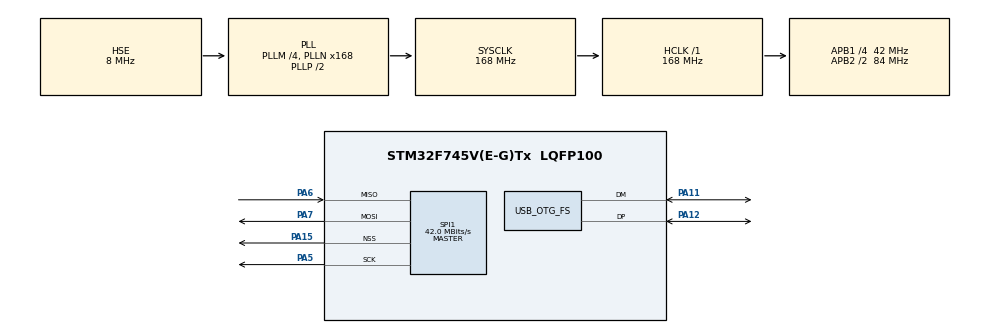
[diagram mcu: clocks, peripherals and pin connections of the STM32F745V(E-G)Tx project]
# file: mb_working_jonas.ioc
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FREERTOS.Mutexes01=sb_1_mutex,Static,myMutex01ControlBlock
FREERTOS.Tasks01=defaultTask,24,128,StartDefaultTask,Default,NULL,Dynamic,NULL,NULL;task_state_est,8,512,vTaskStateEst,Default,NULL,Static,task_sfBuffer,task_sfControlBlock;task_controller,8,512,vTaskController,Default,NULL,Static,task_controllerBuffer,task_controllerControlBlock;task_sens_read,8,512,vTaskSensRead,Default,NULL,Static,task_sensor_reaBuffer,task_sensor_reaControlBlock
Mcu.Family=STM32F7
Mcu.Name=STM32F745V(E-G)Tx
Mcu.Package=LQFP100
NVIC.OTG_FS_IRQn=true\:5\:0\:false\:false\:true\:true\:false\:true
NVIC.PriorityGroup=NVIC_PRIORITYGROUP_4
NVIC.TIM1_UP_TIM10_IRQn=true\:0\:0\:false\:false\:true\:false\:false\:true
NVIC.TimeBase=TIM1_UP_TIM10_IRQn
NVIC.TimeBaseIP=TIM1
PA11.Mode=Device_Only
PA11.Signal=USB_OTG_FS_DM
PA12.Mode=Device_Only
PA12.Signal=USB_OTG_FS_DP
PA15.Mode=NSS_Signal_Hard_Output
PA15.Signal=SPI1_NSS
PA5.Mode=Full_Duplex_Master
PA5.Signal=SPI1_SCK
PA6.Mode=Full_Duplex_Master
PA6.Signal=SPI1_MISO
PA7.Mode=Full_Duplex_Master
PA7.Signal=SPI1_MOSI
PH0/OSC_IN.Mode=HSE-External-Oscillator
PH0/OSC_IN.Signal=RCC_OSC_IN
PH1/OSC_OUT.Mode=HSE-External-Oscillator
PH1/OSC_OUT.Signal=RCC_OSC_OUT
ProjectManager.HeapSize=0x400
ProjectManager.StackSize=0x800
ProjectManager.TargetToolchain=STM32CubeIDE
RCC.AHBFreq_Value=168000000
RCC.APB1CLKDivider=RCC_HCLK_DIV4
RCC.APB1Freq_Value=42000000
RCC.APB1TimFreq_Value=84000000
RCC.APB2CLKDivider=RCC_HCLK_DIV2
RCC.APB2Freq_Value=84000000
RCC.APB2TimFreq_Value=168000000
RCC.CortexFreq_Value=168000000
RCC.HCLKFreq_Value=168000000
RCC.HSE_VALUE=8000000
RCC.HSI_VALUE=16000000
RCC.LSE_VALUE=32768
RCC.PLLM=4
RCC.PLLN=168
RCC.PLLQ=7
RCC.SYSCLKFreq_VALUE=168000000
RCC.SYSCLKSource=RCC_SYSCLKSOURCE_PLLCLK
RCC.USBFreq_Value=48000000
RCC.VCOOutputFreq_Value=336000000
SPI1.CalculateBaudRate=42.0 MBits/s
SPI1.DataSize=SPI_DATASIZE_8BIT
SPI1.Direction=SPI_DIRECTION_2LINES
SPI1.Mode=SPI_MODE_MASTER
SPI1.VirtualNSS=VM_NSSHARD
SPI1.VirtualType=VM_MASTER
USB_DEVICE.CLASS_NAME_FS=CDC
USB_DEVICE.VirtualMode-CDC_FS=Cdc
USB_DEVICE.VirtualModeFS=Cdc_FS
USB_OTG_FS.VirtualMode=Device_Only
VP_FREERTOS_VS_CMSIS_V2.Mode=CMSIS_V2
VP_SYS_VS_tim1.Mode=TIM1
VP_USB_DEVICE_VS_USB_DEVICE_CDC_FS.Mode=CDC_FS
board=custom

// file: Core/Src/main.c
/* USER CODE BEGIN Header */
/**
  ******************************************************************************
  * @file           : main.c
  * @brief          : Main program body
  ******************************************************************************
  * @attention
  *
  * <h2><center>&copy; Copyright (c) 2020 STMicroelectronics.
  * All rights reserved.</center></h2>
  *
  * This software component is licensed by ST under BSD 3-Clause license,
  * the "License"; You may not use this file except in compliance with the
  * License. You may obtain a copy of the License at:
  *                        opensource.org/licenses/BSD-3-Clause
  *
  ******************************************************************************
  */
/* USER CODE END Header */

#include "main.h"
#include "cmsis_os.h"
#include "usb_device.h"

/* USER CODE BEGIN Includes */
#include "tasks/task_controller.h"
#include "tasks/task_sens_read.h"
#include "tasks/task_state_est.h"
#include "typedef.h"
/* USER CODE END Includes */

SPI_HandleTypeDef hspi1;

typedef StaticTask_t osStaticThreadDef_t;
typedef StaticSemaphore_t osStaticMutexDef_t;
osThreadId_t defaultTaskHandle;
osThreadId_t task_state_estHandle;
uint32_t task_sfBuffer[ 512 ];
osStaticThreadDef_t task_sfControlBlock;
osThreadId_t task_controllerHandle;
uint32_t task_controllerBuffer[ 512 ];
osStaticThreadDef_t task_controllerControlBlock;
osThreadId_t task_sens_readHandle;
uint32_t task_sensor_reaBuffer[ 512 ];
osStaticThreadDef_t task_sensor_reaControlBlock;
osMutexId_t sb_1_mutexHandle;
osStaticMutexDef_t myMutex01ControlBlock;
/* USER CODE BEGIN PV */
baro_data sb1_baro;
imu_data sb1_imu;

/* USER CODE END PV */

void SystemClock_Config(void);
static void MX_GPIO_Init(void);
static void MX_SPI1_Init(void);
void StartDefaultTask(void *argument);
void vTaskStateEst(void *argument);
void vTaskController(void *argument);
void vTaskSensRead(void *argument);

int main(void)
{

  /* MCU Configuration--------------------------------------------------------*/

  /* Reset of all peripherals, Initializes the Flash interface and the Systick. */
  HAL_Init();

  /* Configure the system clock */
  SystemClock_Config();

  /* Initialize all configured peripherals */
  MX_GPIO_Init();
  MX_SPI1_Init();

  osKernelInitialize();

  /* Create the mutex(es) */
  /* definition and creation of sb_1_mutex */
  const osMutexAttr_t sb_1_mutex_attributes = {
    .name = "sb_1_mutex",
    .cb_mem = &myMutex01ControlBlock,
    .cb_size = sizeof(myMutex01ControlBlock),
  };
  sb_1_mutexHandle = osMutexNew(&sb_1_mutex_attributes);

  /* Create the thread(s) */
  /* definition and creation of defaultTask */
  const osThreadAttr_t defaultTask_attributes = {
    .name = "defaultTask",
    .priority = (osPriority_t) osPriorityNormal,
    .stack_size = 128
  };
  defaultTaskHandle = osThreadNew(StartDefaultTask, NULL, &defaultTask_attributes);

  /* definition and creation of task_state_est */
  const osThreadAttr_t task_state_est_attributes = {
    .name = "task_state_est",
    .stack_mem = &task_sfBuffer[0],
    .stack_size = sizeof(task_sfBuffer),
    .cb_mem = &task_sfControlBlock,
    .cb_size = sizeof(task_sfControlBlock),
    .priority = (osPriority_t) osPriorityLow,
  };
  task_state_estHandle = osThreadNew(vTaskStateEst, NULL, &task_state_est_attributes);

  /* definition and creation of task_controller */
  const osThreadAttr_t task_controller_attributes = {
    .name = "task_controller",
    .stack_mem = &task_controllerBuffer[0],
    .stack_size = sizeof(task_controllerBuffer),
    .cb_mem = &task_controllerControlBlock,
    .cb_size = sizeof(task_controllerControlBlock),
    .priority = (osPriority_t) osPriorityLow,
  };
  task_controllerHandle = osThreadNew(vTaskController, NULL, &task_controller_attributes);

  /* definition and creation of task_sens_read */
  const osThreadAttr_t task_sens_read_attributes = {
    .name = "task_sens_read",
    .stack_mem = &task_sensor_reaBuffer[0],
    .stack_size = sizeof(task_sensor_reaBuffer),
    .cb_mem = &task_sensor_reaControlBlock,
    .cb_size = sizeof(task_sensor_reaControlBlock),
    .priority = (osPriority_t) osPriorityLow,
  };
  task_sens_readHandle = osThreadNew(vTaskSensRead, NULL, &task_sens_read_attributes);

  /* Start scheduler */
  osKernelStart();

  /* We should never get here as control is now taken by the scheduler */

  /* Infinite loop */
  while (1)
  {
  }
}

void SystemClock_Config(void)
{
  RCC_OscInitTypeDef RCC_OscInitStruct = {0};
  RCC_ClkInitTypeDef RCC_ClkInitStruct = {0};
  RCC_PeriphCLKInitTypeDef PeriphClkInitStruct = {0};

  /** Configure the main internal regulator output voltage
  */
  __HAL_RCC_PWR_CLK_ENABLE();
  __HAL_PWR_VOLTAGESCALING_CONFIG(PWR_REGULATOR_VOLTAGE_SCALE2);
  /** Initializes the CPU, AHB and APB busses clocks
  */
  RCC_OscInitStruct.OscillatorType = RCC_OSCILLATORTYPE_HSE;
  RCC_OscInitStruct.HSEState = RCC_HSE_ON;
  RCC_OscInitStruct.PLL.PLLState = RCC_PLL_ON;
  RCC_OscInitStruct.PLL.PLLSource = RCC_PLLSOURCE_HSE;
  RCC_OscInitStruct.PLL.PLLM = 4;
  RCC_OscInitStruct.PLL.PLLN = 168;
  RCC_OscInitStruct.PLL.PLLP = RCC_PLLP_DIV2;
  RCC_OscInitStruct.PLL.PLLQ = 7;
  if (HAL_RCC_OscConfig(&RCC_OscInitStruct) != HAL_OK)
  {
    Error_Handler();
  }
  /** Initializes the CPU, AHB and APB busses clocks
  */
  RCC_ClkInitStruct.ClockType = RCC_CLOCKTYPE_HCLK|RCC_CLOCKTYPE_SYSCLK
                              |RCC_CLOCKTYPE_PCLK1|RCC_CLOCKTYPE_PCLK2;
  RCC_ClkInitStruct.SYSCLKSource = RCC_SYSCLKSOURCE_PLLCLK;
  RCC_ClkInitStruct.AHBCLKDivider = RCC_SYSCLK_DIV1;
  RCC_ClkInitStruct.APB1CLKDivider = RCC_HCLK_DIV4;
  RCC_ClkInitStruct.APB2CLKDivider = RCC_HCLK_DIV2;

  if (HAL_RCC_ClockConfig(&RCC_ClkInitStruct, FLASH_LATENCY_5) != HAL_OK)
  {
    Error_Handler();
  }
  PeriphClkInitStruct.PeriphClockSelection = RCC_PERIPHCLK_CLK48;
  PeriphClkInitStruct.Clk48ClockSelection = RCC_CLK48SOURCE_PLL;
  if (HAL_RCCEx_PeriphCLKConfig(&PeriphClkInitStruct) != HAL_OK)
  {
    Error_Handler();
  }
}

static void MX_SPI1_Init(void)
{

  /* SPI1 parameter configuration*/
  hspi1.Instance = SPI1;
  hspi1.Init.Mode = SPI_MODE_MASTER;
  hspi1.Init.Direction = SPI_DIRECTION_2LINES;
  hspi1.Init.DataSize = SPI_DATASIZE_8BIT;
  hspi1.Init.CLKPolarity = SPI_POLARITY_LOW;
  hspi1.Init.CLKPhase = SPI_PHASE_1EDGE;
  hspi1.Init.NSS = SPI_NSS_HARD_OUTPUT;
  hspi1.Init.BaudRatePrescaler = SPI_BAUDRATEPRESCALER_2;
  hspi1.Init.FirstBit = SPI_FIRSTBIT_MSB;
  hspi1.Init.TIMode = SPI_TIMODE_DISABLE;
  hspi1.Init.CRCCalculation = SPI_CRCCALCULATION_DISABLE;
  hspi1.Init.CRCPolynomial = 7;
  hspi1.Init.CRCLength = SPI_CRC_LENGTH_DATASIZE;
  hspi1.Init.NSSPMode = SPI_NSS_PULSE_ENABLE;
  if (HAL_SPI_Init(&hspi1) != HAL_OK)
  {
    Error_Handler();
  }

}

static void MX_GPIO_Init(void)
{

  /* GPIO Ports Clock Enable */
  __HAL_RCC_GPIOH_CLK_ENABLE();
  __HAL_RCC_GPIOA_CLK_ENABLE();

}

void StartDefaultTask(void *argument)
{
  /* init code for USB_DEVICE */
  MX_USB_DEVICE_Init();
  for(;;)
  {
    osDelay(1);
  }
}

void HAL_TIM_PeriodElapsedCallback(TIM_HandleTypeDef *htim)
{
  if (htim->Instance == TIM1) {
    HAL_IncTick();
  }
}

void Error_Handler(void)
{
}

/************************ (C) COPYRIGHT STMicroelectronics *****END OF FILE****/
